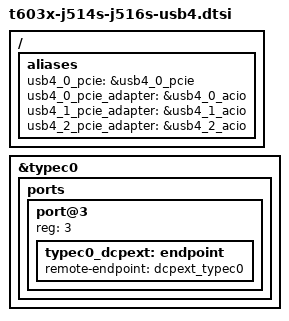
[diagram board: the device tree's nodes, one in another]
// SPDX-License-Identifier: GPL-2.0+ OR MIT
/* Additional loader aliases for the T6030 PCIe adapter tunables. */

/ {
	aliases {
		usb4_0_pcie = &usb4_0_pcie;
		usb4_0_pcie_adapter = &usb4_0_acio;
		usb4_1_pcie_adapter = &usb4_1_acio;
		usb4_2_pcie_adapter = &usb4_2_acio;
	};
};

&typec0 {
	ports {
		port@3 {
			reg = <3>;
			typec0_dcpext: endpoint {
				remote-endpoint = <&dcpext_typec0>;
			};
		};
	};
};

